AUTOSAR XML (schema 00048)
package /ComponentTypes
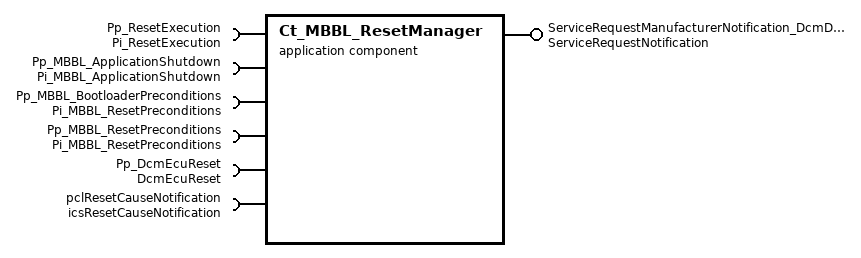
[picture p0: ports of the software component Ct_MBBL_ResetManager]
  application sw component type Ct_MBBL_ResetManager
    require port Pp_ResetExecution: required-com-specs=[HardReset, SoftReset], required-interface=Pi_ResetExecution
    provide port ServiceRequestManufacturerNotification_DcmDslServiceRequestManufacturerNotification_ResetPreconditionCheck: provided-com-specs=[{operation=Indication, queue-length=1}, {operation=Confirmation, queue-length=1}], provided-interface=ServiceRequestNotification
    5 x require port:
      Pp_MBBL_ApplicationShutdown: required-com-specs=[ShutdownAppl_HardReset, ShutdownAppl_SoftReset], required-interface=Pi_MBBL_ApplicationShutdown
      Pp_MBBL_BootloaderPreconditions: client-com-spec=CheckConditions, required-interface=Pi_MBBL_ResetPreconditions
      Pp_MBBL_ResetPreconditions: client-com-spec=CheckConditions, required-interface=Pi_MBBL_ResetPreconditions
      Pp_DcmEcuReset: mode-switch-receiver-com-spec{enhanced-mode-api=true, mode-group=DcmEcuReset}, required-interface=DcmEcuReset
      pclResetCauseNotification: client-com-spec=NotifyResetCause, required-interface=icsResetCauseNotification
    behavior Ct_MBBL_ResetManager_InternalBehavior: data-type-mapping=DataTypeMappingSet_PP4G
      operation invoked event OIT_ServiceRequestManufacturerNotification_DcmDslServiceRequestManufacturerNotification_ResetPreconditionCheck_Confirmat0D82719D: start-on-event=DcmDslServiceRequestManufacturerNotification_ResetPreconditionCheck_Confirmation, operation=ServiceRequestManufacturerNotification_DcmDslServiceRequestManufacturerNotification_ResetPreconditionCheck.Confirmation
      operation invoked event OIT_ServiceRequestManufacturerNotification_DcmDslServiceRequestManufacturerNotification_ResetPreconditionCheck_Indicatio9245E1B1: start-on-event=DcmDslServiceRequestManufacturerNotification_ResetPreconditionCheck_Indication, operation=ServiceRequestManufacturerNotification_DcmDslServiceRequestManufacturerNotification_ResetPreconditionCheck.Indication
      init event Ct_MBBL_ResetManager_InitEvent: start-on-event=Ct_MBBL_ResetManager_Init
      5 x swc mode switch event, all with start-on-event=ResetServiceExecution, activation=ON-ENTRY:
        MST_ResetServiceExecution_0: mode=Pp_DcmEcuReset.DcmEcuReset.EXECUTE
        MST_ResetServiceExecution_1: mode=Pp_DcmEcuReset.DcmEcuReset.HARD
        MST_ResetServiceExecution_2: mode=Pp_DcmEcuReset.DcmEcuReset.JUMPTOBOOTLOADER
        MST_ResetServiceExecution_3: mode=Pp_DcmEcuReset.DcmEcuReset.JUMPTOSYSSUPPLIERBOOTLOADER
        MST_ResetServiceExecution_4: mode=Pp_DcmEcuReset.DcmEcuReset.SOFT
      4 x runnable:
        DcmDslServiceRequestManufacturerNotification_ResetPreconditionCheck_Confirmation  # ------------------------------------------------------------------------------------- This runnable is currently not used, but since there is no way to generate the _Indication-runnable without this, it must be implemented nevertheless. -------------------------------------------------------------------------------------
        DcmDslServiceRequestManufacturerNotification_ResetPreconditionCheck_Indication  # ------------------------------------------------------------------------------------- This runnable called whenever any diagnostic request is received by the ECU. It performs the following checks: Service $10 - Programming Session (0x02): Checks preconditions for this request by calling services provided by Pp_MBBL_BootloaderPreconditions and triggers the DCM to send negative response codes if those fail. Service $11 - Soft-Reset (0x01) or Hard-Reset (0x03): Checks preconditions for this request by calling services provided by Pp_MBBL_ResetPreconditions and triggers the DCM to send negative response codes if those fail. -------------------------------------------------------------------------------------
          sync call SC_Pp_MBBL_BootloaderPreconditions_CheckConditions: operation=Pp_MBBL_BootloaderPreconditions.CheckConditions
          sync call SC_Pp_MBBL_ResetPreconditions_CheckConditions: operation=Pp_MBBL_ResetPreconditions.CheckConditions
        Ct_MBBL_ResetManager_Init  # ------------------------------------------------------------------------------------- This runnable is currently not used. -------------------------------------------------------------------------------------
        ResetServiceExecution: mode-access-point=Pp_DcmEcuReset.DcmEcuReset  # ------------------------------------------------------------------------------------- This runnable is executed by the DCM multiple times during reset procedure. It checks the required reset mode and triggers the application to shut down by calling the services provided by Pp_MBBL_ApplicationShutdown. After this it requests the actual reset by calling the services provided by Pp_ResetExecution. -------------------------------------------------------------------------------------
          4 x sync call:
            SC_Pp_MBBL_ApplicationShutdown_ShutdownAppl_HardReset: operation=Pp_MBBL_ApplicationShutdown.ShutdownAppl_HardReset
            SC_Pp_MBBL_ApplicationShutdown_ShutdownAppl_SoftReset: operation=Pp_MBBL_ApplicationShutdown.ShutdownAppl_SoftReset
            SC_Pp_ResetExecution_HardReset: operation=Pp_ResetExecution.HardReset
            SC_Pp_ResetExecution_SoftReset: operation=Pp_ResetExecution.SoftReset
  swc implementation Ct_MBBL_ResetManager_Implementation: behavior=Ct_MBBL_ResetManager_InternalBehavior
    code-descriptors:
      code Default: artifact-descriptors=autosar-engineering-object=category=SWSRC
